AUTOSAR XML (schema 4-2-2)
package /Components
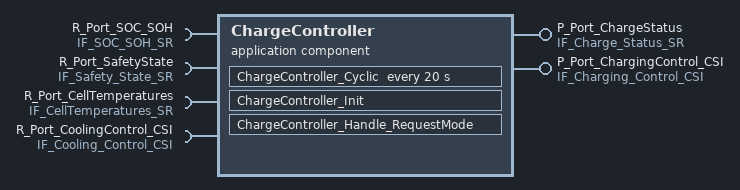
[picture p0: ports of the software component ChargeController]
  application sw component type ChargeController
    provide port P_Port_ChargeStatus: provided-interface=IF_Charge_Status_SR
    provide port P_Port_ChargingControl_CSI: provided-interface=IF_Charging_Control_CSI
    4 x require port:
      R_Port_SOC_SOH: required-interface=IF_SOC_SOH_SR
      R_Port_SafetyState: required-interface=IF_Safety_State_SR
      R_Port_CellTemperatures: required-interface=IF_CellTemperatures_SR
      R_Port_CoolingControl_CSI: required-interface=IF_Cooling_Control_CSI
    behavior ChargeController_InternalBehavior
      init event ChargeController_Init_Event: start-on-event=ChargeController_Init
      operation invoked event Charging_RequestMode_Invoked: start-on-event=ChargeController_Handle_RequestMode, operation=P_Port_ChargingControl_CSI.RequestChargeMode
      timing event ChargeController_20ms_Event: start-on-event=ChargeController_Cyclic, period=20
      runnable ChargeController_Init
        data-send-points:
          access VA_Init_ChargeMode: accessed-variable=P_Port_ChargeStatus.ChargeMode
          access VA_Init_ChargeCurrentSetpoint: accessed-variable=P_Port_ChargeStatus.ChargeCurrentSetpoint
          access VA_Init_ChargeFault: accessed-variable=P_Port_ChargeStatus.ChargeFault
      runnable ChargeController_Cyclic: minimum-start-interval=20
        data-receive-point-by-values:
          6 x access:
            VA_Cyc_Read_PackSOC: accessed-variable=R_Port_SOC_SOH.PackSOC
            VA_Cyc_Read_PackSOH: accessed-variable=R_Port_SOC_SOH.PackSOH
            VA_Cyc_Read_SafetyState: accessed-variable=R_Port_SafetyState.SafetyState
            VA_Cyc_Read_FaultCode: accessed-variable=R_Port_SafetyState.FaultCode
            VA_Cyc_Read_PackTemperature: accessed-variable=R_Port_CellTemperatures.PackTemperature
            VA_Cyc_Read_CellTemperatures_Array: accessed-variable=R_Port_CellTemperatures.CellTemperatures_Array
        data-send-points:
          access VA_Cyc_Send_ChargeMode: accessed-variable=P_Port_ChargeStatus.ChargeMode
          access VA_Cyc_Send_ChargeCurrentSetpoint: accessed-variable=P_Port_ChargeStatus.ChargeCurrentSetpoint
          access VA_Cyc_Send_ChargeFault: accessed-variable=P_Port_ChargeStatus.ChargeFault
        sync call SCP_Cyc_SetCoolingMode: operation=R_Port_CoolingControl_CSI.SetCoolingMode, timeout=20
        sync call SCP_Cyc_SetCoolantPumpSpeed: operation=R_Port_CoolingControl_CSI.SetCoolantPumpSpeed, timeout=20
        sync call SCP_Cyc_SetFanSpeed: operation=R_Port_CoolingControl_CSI.SetFanSpeed, timeout=20
      runnable ChargeController_Handle_RequestMode
        data-receive-point-by-arguments:
          access VA_Handle_Arg_ChargeMode: accessed-variable=P_Port_ChargingControl_CSI.ChargeMode
        data-receive-point-by-values:
          access VA_Handle_Read_SafetyState: accessed-variable=R_Port_SafetyState.SafetyState
        data-send-points:
          access VA_Handle_Send_ChargeMode: accessed-variable=P_Port_ChargeStatus.ChargeMode
          access VA_Handle_Send_ChargeFault: accessed-variable=P_Port_ChargeStatus.ChargeFault
